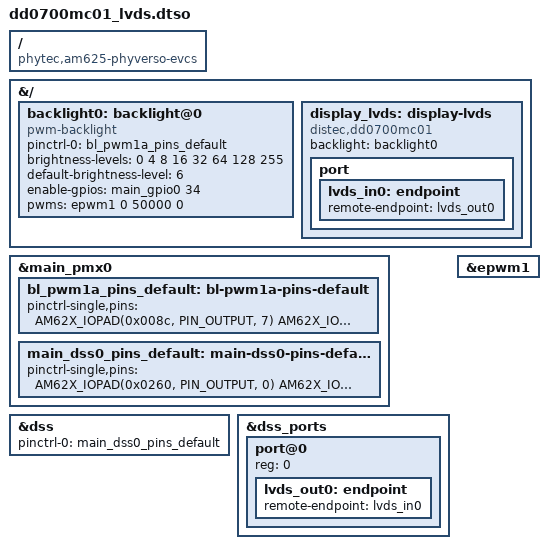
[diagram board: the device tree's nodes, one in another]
// SPDX-License-Identifier: GPL-2.0
/*
 * Copyright (C) 2022 - 2023 PHYTEC Messtechnik GmbH
 * Author: Alexander Bauer <a.bauer@phytec.de>
 *
 * Product homepage:
 * https://www.phytec.com/product/phyboard-am62x
 */

#include <dt-bindings/gpio/gpio.h>
#include <dt-bindings/input/input.h>
#include <dt-bindings/leds/common.h>
#include <dt-bindings/net/ti-dp83867.h>
#include "k3-pinctrl.h"

/dts-v1/;
/plugin/;

/ {
        compatible = "phytec,am625-phyverso-evcs",
                     "phytec,am62-phycore-som", "ti,am625";
};

&{/} {
	backlight0: backlight@0 {
		pinctrl-names = "default";
		pinctrl-0 = <&bl_pwm1a_pins_default>;

		compatible = "pwm-backlight";

		brightness-levels = <0 4 8 16 32 64 128 255>;
		default-brightness-level = <6>;

		enable-gpios = <&main_gpio0 34 GPIO_ACTIVE_HIGH>;
		pwms = <&epwm1 0 50000 0>;
	};

	display_lvds: display-lvds {
		compatible = "distec,dd0700mc01";
		backlight = <&backlight0>;

		port {
			lvds_in0: endpoint {
				remote-endpoint = <&lvds_out0>;
			};
		};
	};
};

&main_pmx0 {
	pinctrl-names = "default";

	bl_pwm1a_pins_default: bl-pwm1a-pins-default {
		pinctrl-single,pins = <
			AM62X_IOPAD(0x008c, PIN_OUTPUT, 7) /* (L25) GPMC0_WEn.GPIO0_34 */
			AM62X_IOPAD(0x019c, PIN_OUTPUT, 6) /* (B18) MCASP0_AXR1.EHRPWM1_A */
		>;
	};

	main_dss0_pins_default: main-dss0-pins-default {
		pinctrl-single,pins = <
			AM62X_IOPAD(0x0260, PIN_OUTPUT, 0) /* (AA5) OLDI0_A0N */
			AM62X_IOPAD(0x025c, PIN_OUTPUT, 0) /* (Y6) OLDI0_A0P */
			AM62X_IOPAD(0x0268, PIN_OUTPUT, 0) /* (AD3) OLDI0_A1N */
			AM62X_IOPAD(0x0264, PIN_OUTPUT, 0) /* (AB4) OLDI0_A1P */
			AM62X_IOPAD(0x0270, PIN_OUTPUT, 0) /* (Y8) OLDI0_A2N */
			AM62X_IOPAD(0x026c, PIN_OUTPUT, 0) /* (AA8) OLDI0_A2P */
			AM62X_IOPAD(0x0278, PIN_OUTPUT, 0) /* (AB6) OLDI0_A3N */
			AM62X_IOPAD(0x0274, PIN_OUTPUT, 0) /* (AA7) OLDI0_A3P */
			AM62X_IOPAD(0x02a0, PIN_OUTPUT, 0) /* (AD4) OLDI0_CLK0N */
			AM62X_IOPAD(0x029c, PIN_OUTPUT, 0) /* (AE3) OLDI0_CLK0P */
		>;
	};
};

&dss {
	pinctrl-names = "default";
	pinctrl-0 = <&main_dss0_pins_default>;
	status = "okay";
};

&dss_ports {
	#address-cells = <1>;
	#size-cells = <0>;
	status = "okay";

	/* VP1: LVDS Output */
	port@0 {
		reg = <0>;

		lvds_out0: endpoint {
			remote-endpoint = <&lvds_in0>;
		};
	};
};

&epwm1 {
	status = "okay";
};

